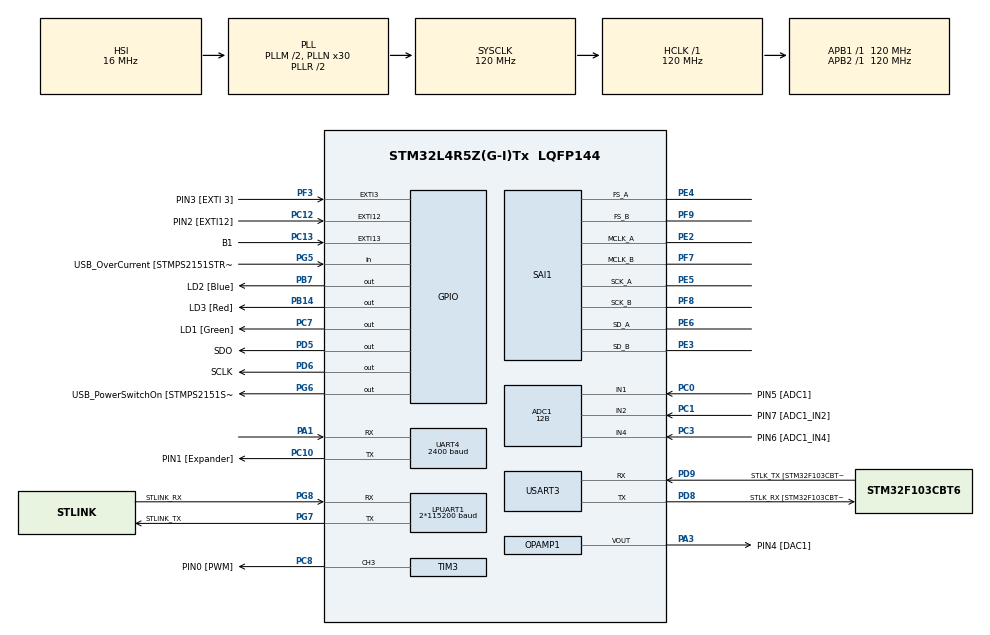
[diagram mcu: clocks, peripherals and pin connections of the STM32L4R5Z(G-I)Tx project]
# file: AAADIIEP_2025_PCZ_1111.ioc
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ADC1.Channel-1\#ChannelRegularConversion=ADC_CHANNEL_1
ADC1.Channel-2\#ChannelRegularConversion=ADC_CHANNEL_2
ADC1.Channel-3\#ChannelRegularConversion=ADC_CHANNEL_4
ADC1.Channel-4\#ChannelRegularConversion=ADC_CHANNEL_TEMPSENSOR
ADC1.Channel-5\#ChannelRegularConversion=ADC_CHANNEL_VBAT
ADC1.ClockPrescaler=ADC_CLOCK_ASYNC_DIV2
ADC1.ContinuousConvMode=DISABLE
ADC1.DMAContinuousRequests=ENABLE
ADC1.ExternalTrigConv=ADC_EXTERNALTRIG_T15_TRGO
ADC1.NbrOfConversion=5
ADC1.NbrOfConversionFlag=1
ADC1.OffsetNumber-1\#ChannelRegularConversion=ADC_OFFSET_NONE
ADC1.OffsetNumber-2\#ChannelRegularConversion=ADC_OFFSET_NONE
ADC1.OffsetNumber-3\#ChannelRegularConversion=ADC_OFFSET_NONE
ADC1.OffsetNumber-4\#ChannelRegularConversion=ADC_OFFSET_NONE
ADC1.OffsetNumber-5\#ChannelRegularConversion=ADC_OFFSET_NONE
ADC1.Rank-1\#ChannelRegularConversion=1
ADC1.Rank-2\#ChannelRegularConversion=2
ADC1.Rank-3\#ChannelRegularConversion=3
ADC1.Rank-4\#ChannelRegularConversion=4
ADC1.Rank-5\#ChannelRegularConversion=5
ADC1.Resolution=ADC_RESOLUTION_12B
ADC1.SamplingTime-1\#ChannelRegularConversion=ADC_SAMPLETIME_92CYCLES_5
ADC1.SamplingTime-2\#ChannelRegularConversion=ADC_SAMPLETIME_92CYCLES_5
ADC1.SamplingTime-3\#ChannelRegularConversion=ADC_SAMPLETIME_92CYCLES_5
ADC1.SamplingTime-4\#ChannelRegularConversion=ADC_SAMPLETIME_92CYCLES_5
ADC1.SamplingTime-5\#ChannelRegularConversion=ADC_SAMPLETIME_92CYCLES_5
ADC1.master=1
DAC1.DAC_SampleAndHold-DAC_OUT1_Int=DAC_SAMPLEANDHOLD_DISABLE
DAC1.DAC_Trigger-DAC_OUT1_Int=DAC_TRIGGER_T15_TRGO
DAC1.DAC_UserTrimming-DAC_OUT1_Int=DAC_TRIMMING_FACTORY
Dma.ADC1.3.Direction=DMA_PERIPH_TO_MEMORY
Dma.ADC1.3.EventEnable=DISABLE
Dma.ADC1.3.Instance=DMA2_Channel2
Dma.ADC1.3.MemDataAlignment=DMA_MDATAALIGN_HALFWORD
Dma.ADC1.3.MemInc=DMA_MINC_ENABLE
Dma.ADC1.3.Mode=DMA_CIRCULAR
Dma.ADC1.3.PeriphDataAlignment=DMA_PDATAALIGN_HALFWORD
Dma.ADC1.3.PeriphInc=DMA_PINC_DISABLE
Dma.ADC1.3.Polarity=HAL_DMAMUX_REQUEST_GEN_RISING
Dma.ADC1.3.Priority=DMA_PRIORITY_MEDIUM
Dma.ADC1.3.RequestNumber=1
Dma.ADC1.3.SignalID=NONE
Dma.ADC1.3.SyncEnable=DISABLE
Dma.ADC1.3.SyncPolarity=HAL_DMAMUX_SYNC_NO_EVENT
Dma.ADC1.3.SyncRequestNumber=1
Dma.ADC1.3.SyncSignalID=NONE
Dma.DAC1_CH1.2.Direction=DMA_MEMORY_TO_PERIPH
Dma.DAC1_CH1.2.EventEnable=DISABLE
Dma.DAC1_CH1.2.Instance=DMA1_Channel6
Dma.DAC1_CH1.2.MemDataAlignment=DMA_MDATAALIGN_HALFWORD
Dma.DAC1_CH1.2.MemInc=DMA_MINC_ENABLE
Dma.DAC1_CH1.2.Mode=DMA_CIRCULAR
Dma.DAC1_CH1.2.PeriphDataAlignment=DMA_PDATAALIGN_HALFWORD
Dma.DAC1_CH1.2.PeriphInc=DMA_PINC_DISABLE
Dma.DAC1_CH1.2.Polarity=HAL_DMAMUX_REQUEST_GEN_RISING
Dma.DAC1_CH1.2.Priority=DMA_PRIORITY_HIGH
Dma.DAC1_CH1.2.RequestNumber=1
Dma.DAC1_CH1.2.SignalID=NONE
Dma.DAC1_CH1.2.SyncEnable=DISABLE
Dma.DAC1_CH1.2.SyncPolarity=HAL_DMAMUX_SYNC_NO_EVENT
Dma.DAC1_CH1.2.SyncRequestNumber=1
Dma.DAC1_CH1.2.SyncSignalID=NONE
Dma.LPUART1_RX.0.Direction=DMA_PERIPH_TO_MEMORY
Dma.LPUART1_RX.0.EventEnable=DISABLE
Dma.LPUART1_RX.0.Instance=DMA1_Channel1
Dma.LPUART1_RX.0.MemDataAlignment=DMA_MDATAALIGN_BYTE
Dma.LPUART1_RX.0.MemInc=DMA_MINC_ENABLE
Dma.LPUART1_RX.0.Mode=DMA_NORMAL
Dma.LPUART1_RX.0.PeriphDataAlignment=DMA_PDATAALIGN_BYTE
Dma.LPUART1_RX.0.PeriphInc=DMA_PINC_DISABLE
Dma.LPUART1_RX.0.Polarity=HAL_DMAMUX_REQUEST_GEN_RISING
Dma.LPUART1_RX.0.Priority=DMA_PRIORITY_LOW
Dma.LPUART1_RX.0.RequestNumber=1
Dma.LPUART1_RX.0.SignalID=NONE
Dma.LPUART1_RX.0.SyncEnable=DISABLE
Dma.LPUART1_RX.0.SyncPolarity=HAL_DMAMUX_SYNC_NO_EVENT
Dma.LPUART1_RX.0.SyncRequestNumber=1
Dma.LPUART1_RX.0.SyncSignalID=NONE
Dma.LPUART1_TX.1.Direction=DMA_MEMORY_TO_PERIPH
Dma.LPUART1_TX.1.EventEnable=DISABLE
Dma.LPUART1_TX.1.Instance=DMA1_Channel2
Dma.LPUART1_TX.1.MemDataAlignment=DMA_MDATAALIGN_BYTE
Dma.LPUART1_TX.1.MemInc=DMA_MINC_ENABLE
Dma.LPUART1_TX.1.Mode=DMA_NORMAL
Dma.LPUART1_TX.1.PeriphDataAlignment=DMA_PDATAALIGN_BYTE
Dma.LPUART1_TX.1.PeriphInc=DMA_PINC_DISABLE
Dma.LPUART1_TX.1.Polarity=HAL_DMAMUX_REQUEST_GEN_RISING
Dma.LPUART1_TX.1.Priority=DMA_PRIORITY_LOW
Dma.LPUART1_TX.1.RequestNumber=1
Dma.LPUART1_TX.1.SignalID=NONE
Dma.LPUART1_TX.1.SyncEnable=DISABLE
Dma.LPUART1_TX.1.SyncPolarity=HAL_DMAMUX_SYNC_NO_EVENT
Dma.LPUART1_TX.1.SyncRequestNumber=1
Dma.LPUART1_TX.1.SyncSignalID=NONE
Dma.MEMTOMEM.8.Direction=DMA_MEMORY_TO_MEMORY
Dma.MEMTOMEM.8.EventEnable=DISABLE
Dma.MEMTOMEM.8.Instance=DMA1_Channel7
Dma.MEMTOMEM.8.MemDataAlignment=DMA_MDATAALIGN_HALFWORD
Dma.MEMTOMEM.8.MemInc=DMA_MINC_ENABLE
Dma.MEMTOMEM.8.Mode=DMA_NORMAL
Dma.MEMTOMEM.8.PeriphDataAlignment=DMA_PDATAALIGN_HALFWORD
Dma.MEMTOMEM.8.PeriphInc=DMA_PINC_ENABLE
Dma.MEMTOMEM.8.Polarity=HAL_DMAMUX_REQUEST_GEN_RISING
Dma.MEMTOMEM.8.Priority=DMA_PRIORITY_MEDIUM
Dma.MEMTOMEM.8.RequestNumber=1
Dma.MEMTOMEM.8.SignalID=NONE
Dma.MEMTOMEM.8.SyncEnable=DISABLE
Dma.MEMTOMEM.8.SyncPolarity=HAL_DMAMUX_SYNC_NO_EVENT
Dma.MEMTOMEM.8.SyncRequestNumber=1
Dma.MEMTOMEM.8.SyncSignalID=NONE
Dma.Request0=LPUART1_RX
Dma.Request1=LPUART1_TX
Dma.Request2=DAC1_CH1
Dma.Request3=ADC1
Dma.Request4=TIM3_CH3
Dma.Request5=UART4_TX
Dma.Request6=SAI1_A
Dma.Request7=SAI1_B
Dma.Request8=MEMTOMEM
Dma.SAI1_A.6.Direction=DMA_MEMORY_TO_PERIPH
Dma.SAI1_A.6.EventEnable=DISABLE
Dma.SAI1_A.6.Instance=DMA1_Channel5
Dma.SAI1_A.6.MemDataAlignment=DMA_MDATAALIGN_WORD
Dma.SAI1_A.6.MemInc=DMA_MINC_ENABLE
Dma.SAI1_A.6.Mode=DMA_CIRCULAR
Dma.SAI1_A.6.PeriphDataAlignment=DMA_PDATAALIGN_WORD
Dma.SAI1_A.6.PeriphInc=DMA_PINC_DISABLE
Dma.SAI1_A.6.Polarity=HAL_DMAMUX_REQUEST_GEN_RISING
Dma.SAI1_A.6.Priority=DMA_PRIORITY_LOW
Dma.SAI1_A.6.RequestNumber=1
Dma.SAI1_A.6.SignalID=NONE
Dma.SAI1_A.6.SyncEnable=DISABLE
Dma.SAI1_A.6.SyncPolarity=HAL_DMAMUX_SYNC_NO_EVENT
Dma.SAI1_A.6.SyncRequestNumber=1
Dma.SAI1_A.6.SyncSignalID=NONE
Dma.SAI1_B.7.Direction=DMA_PERIPH_TO_MEMORY
Dma.SAI1_B.7.EventEnable=DISABLE
Dma.SAI1_B.7.Instance=DMA2_Channel1
Dma.SAI1_B.7.MemDataAlignment=DMA_MDATAALIGN_WORD
Dma.SAI1_B.7.MemInc=DMA_MINC_ENABLE
Dma.SAI1_B.7.Mode=DMA_CIRCULAR
Dma.SAI1_B.7.PeriphDataAlignment=DMA_PDATAALIGN_WORD
Dma.SAI1_B.7.PeriphInc=DMA_PINC_DISABLE
Dma.SAI1_B.7.Polarity=HAL_DMAMUX_REQUEST_GEN_RISING
Dma.SAI1_B.7.Priority=DMA_PRIORITY_LOW
Dma.SAI1_B.7.RequestNumber=1
Dma.SAI1_B.7.SignalID=NONE
Dma.SAI1_B.7.SyncEnable=DISABLE
Dma.SAI1_B.7.SyncPolarity=HAL_DMAMUX_SYNC_NO_EVENT
Dma.SAI1_B.7.SyncRequestNumber=1
Dma.SAI1_B.7.SyncSignalID=NONE
Dma.TIM3_CH3.4.Direction=DMA_MEMORY_TO_PERIPH
Dma.TIM3_CH3.4.EventEnable=DISABLE
Dma.TIM3_CH3.4.Instance=DMA1_Channel3
Dma.TIM3_CH3.4.MemDataAlignment=DMA_MDATAALIGN_HALFWORD
Dma.TIM3_CH3.4.MemInc=DMA_MINC_ENABLE
Dma.TIM3_CH3.4.Mode=DMA_CIRCULAR
Dma.TIM3_CH3.4.PeriphDataAlignment=DMA_PDATAALIGN_HALFWORD
Dma.TIM3_CH3.4.PeriphInc=DMA_PINC_DISABLE
Dma.TIM3_CH3.4.Polarity=HAL_DMAMUX_REQUEST_GEN_RISING
Dma.TIM3_CH3.4.Priority=DMA_PRIORITY_LOW
Dma.TIM3_CH3.4.RequestNumber=1
Dma.TIM3_CH3.4.SignalID=NONE
Dma.TIM3_CH3.4.SyncEnable=DISABLE
Dma.TIM3_CH3.4.SyncPolarity=HAL_DMAMUX_SYNC_NO_EVENT
Dma.TIM3_CH3.4.SyncRequestNumber=1
Dma.TIM3_CH3.4.SyncSignalID=NONE
Dma.UART4_TX.5.Direction=DMA_MEMORY_TO_PERIPH
Dma.UART4_TX.5.EventEnable=DISABLE
Dma.UART4_TX.5.Instance=DMA1_Channel4
Dma.UART4_TX.5.MemDataAlignment=DMA_MDATAALIGN_BYTE
Dma.UART4_TX.5.MemInc=DMA_MINC_ENABLE
Dma.UART4_TX.5.Mode=DMA_NORMAL
Dma.UART4_TX.5.PeriphDataAlignment=DMA_PDATAALIGN_BYTE
Dma.UART4_TX.5.PeriphInc=DMA_PINC_DISABLE
Dma.UART4_TX.5.Polarity=HAL_DMAMUX_REQUEST_GEN_RISING
Dma.UART4_TX.5.Priority=DMA_PRIORITY_LOW
Dma.UART4_TX.5.RequestNumber=1
Dma.UART4_TX.5.SignalID=NONE
Dma.UART4_TX.5.SyncEnable=DISABLE
Dma.UART4_TX.5.SyncPolarity=HAL_DMAMUX_SYNC_NO_EVENT
Dma.UART4_TX.5.SyncRequestNumber=1
Dma.UART4_TX.5.SyncSignalID=NONE
LPUART1.BaudRate=2*115200
LPUART1.WordLength=UART_WORDLENGTH_8B
Mcu.Family=STM32L4
Mcu.Name=STM32L4R5Z(G-I)Tx
Mcu.Package=LQFP144
Mcu.UserConstants=Display_TM1637_100kHz,0
NVIC.ADC1_IRQn=true\:0\:0\:false\:false\:true\:true\:true\:true
NVIC.DMA1_Channel1_IRQn=true\:0\:0\:false\:false\:true\:false\:true\:true
NVIC.DMA1_Channel2_IRQn=true\:0\:0\:false\:false\:true\:false\:true\:true
NVIC.DMA1_Channel3_IRQn=true\:0\:0\:false\:false\:true\:false\:true\:true
NVIC.DMA1_Channel4_IRQn=true\:0\:0\:false\:false\:true\:false\:true\:true
NVIC.DMA1_Channel5_IRQn=true\:0\:0\:false\:false\:true\:false\:true\:true
NVIC.DMA1_Channel6_IRQn=true\:0\:0\:false\:false\:true\:false\:true\:true
NVIC.DMA1_Channel7_IRQn=true\:0\:0\:false\:false\:true\:true\:true\:true
NVIC.DMA2_Channel1_IRQn=true\:0\:0\:false\:false\:true\:false\:true\:true
NVIC.DMA2_Channel2_IRQn=true\:0\:0\:false\:false\:true\:false\:true\:true
NVIC.EXTI15_10_IRQn=true\:0\:0\:false\:false\:true\:true\:true\:true
NVIC.EXTI3_IRQn=true\:0\:0\:false\:false\:true\:true\:true\:true
NVIC.LPUART1_IRQn=true\:0\:0\:false\:false\:true\:true\:true\:true
NVIC.PriorityGroup=NVIC_PRIORITYGROUP_4
NVIC.SAI1_IRQn=true\:0\:0\:false\:false\:true\:true\:true\:true
NVIC.TIM1_BRK_TIM15_IRQn=true\:0\:0\:false\:false\:true\:true\:true\:true
NVIC.TIM1_TRG_COM_TIM17_IRQn=true\:0\:0\:false\:false\:true\:true\:true\:true
NVIC.TIM3_IRQn=true\:0\:0\:false\:false\:true\:true\:true\:true
NVIC.TIM6_DAC_IRQn=true\:0\:0\:false\:false\:true\:true\:true\:true
NVIC.TIM7_IRQn=true\:0\:0\:false\:false\:true\:true\:true\:true
NVIC.UART4_IRQn=true\:0\:0\:false\:false\:true\:true\:true\:true
PA1.Mode=Asynchronous
PA1.Signal=UART4_RX
PA10.GPIO_Label=USB_ID
PA10.Signal=USB_OTG_FS_ID
PA11.GPIO_Label=USB_DM
PA11.Signal=USB_OTG_FS_DM
PA12.GPIO_Label=USB_DP
PA12.Signal=USB_OTG_FS_DP
PA13\ (JTMS/SWDIO).GPIO_Label=TMS
PA13\ (JTMS/SWDIO).Mode=Serial_Wire
PA13\ (JTMS/SWDIO).Signal=SYS_JTMS-SWDIO
PA14\ (JTCK/SWCLK).GPIO_Label=TCK
PA14\ (JTCK/SWCLK).Mode=Serial_Wire
PA14\ (JTCK/SWCLK).Signal=SYS_JTCK-SWCLK
PA3.GPIO_Label=PIN4 [DAC1]
PA3.Mode=Follower-DAC_OUT1-INP
PA3.Signal=OPAMP1_VOUT
PA8.GPIO_Label=USB_SOF [TP1]
PA8.Signal=USB_OTG_FS_SOF
PA9.GPIO_Label=USB_VBUS
PA9.Signal=USB_OTG_FS_VBUS
PB14.GPIO_Label=LD3 [Red]
PB14.Signal=GPIO_Output
PB3\ (JTDO/TRACESWO).GPIO_Label=SWO
PB3\ (JTDO/TRACESWO).Signal=SYS_JTDO-SWO
PB7.GPIO_Label=LD2 [Blue]
PB7.Signal=GPIO_Output
PC0.GPIO_Label=PIN5 [ADC1]
PC0.Signal=ADCx_IN1
PC1.GPIO_Label=PIN7 [ADC1_IN2]
PC1.Signal=ADCx_IN2
PC10.GPIO_Label=PIN1 [Expander]
PC10.Mode=Asynchronous
PC10.Signal=UART4_TX
PC12.GPIO_Label=PIN2 [EXTI12]
PC12.GPIO_ModeDefaultEXTI=GPIO_MODE_IT_RISING_FALLING
PC12.Signal=GPXTI12
PC13.GPIO_Label=B1
PC13.GPIO_ModeDefaultEXTI=GPIO_MODE_IT_RISING_FALLING
PC13.Signal=GPXTI13
PC14-OSC32_IN\ (PC14).Mode=LSE-External-Oscillator
PC14-OSC32_IN\ (PC14).Signal=RCC_OSC32_IN
PC15-OSC32_OUT\ (PC15).Mode=LSE-External-Oscillator
PC15-OSC32_OUT\ (PC15).Signal=RCC_OSC32_OUT
PC3.GPIO_Label=PIN6 [ADC1_IN4]
PC3.Signal=ADCx_IN4
PC7.GPIO_Label=LD1 [Green]
PC7.Signal=GPIO_Output
PC8.GPIO_Label=PIN0 [PWM]
PC8.Signal=S_TIM3_CH3
PD5.GPIO_Label=SDO
PD5.Signal=GPIO_Output
PD6.GPIO_Label=SCLK
PD6.Signal=GPIO_Output
PD8.GPIO_Label=STLK_RX [STM32F103CBT6_PA3]
PD8.Mode=Asynchronous
PD8.Signal=USART3_TX
PD9.GPIO_Label=STLK_TX [STM32F103CBT6_PA2]
PD9.Mode=Asynchronous
PD9.Signal=USART3_RX
PE2.Mode=SAI_A_MasterWithClock
PE2.Signal=SAI1_MCLK_A
PE3.Mode=SAI_B_MasterWithClock
PE3.Signal=SAI1_SD_B
PE4.Mode=SAI_A_MasterWithClock
PE4.Signal=SAI1_FS_A
PE5.Mode=SAI_A_MasterWithClock
PE5.Signal=SAI1_SCK_A
PE6.Mode=SAI_A_MasterWithClock
PE6.Signal=SAI1_SD_A
PF3.GPIO_Label=PIN3 [EXTI 3]
PF3.GPIO_ModeDefaultEXTI=GPIO_MODE_IT_RISING_FALLING
PF3.Signal=GPXTI3
PF7.Mode=SAI_B_MasterWithClock
PF7.Signal=SAI1_MCLK_B
PF8.Mode=SAI_B_MasterWithClock
PF8.Signal=SAI1_SCK_B
PF9.Mode=SAI_B_MasterWithClock
PF9.Signal=SAI1_FS_B
PG5.GPIO_Label=USB_OverCurrent [STMPS2151STR_FAULT]
PG5.Signal=GPIO_Input
PG6.GPIO_Label=USB_PowerSwitchOn [STMPS2151STR_EN]
PG6.Signal=GPIO_Output
PG7.GPIO_Label=STLINK_TX
PG7.Mode=Asynchronous
PG7.Signal=LPUART1_TX
PG8.GPIO_Label=STLINK_RX
PG8.Mode=Asynchronous
PG8.Signal=LPUART1_RX
PH0-OSC_IN\ (PH0).Signal=RCC_OSC_IN
PH1-OSC_OUT\ (PH1).Signal=RCC_OSC_OUT
ProjectManager.HeapSize=0x200
ProjectManager.StackSize=0x400
ProjectManager.TargetToolchain=STM32CubeIDE
RCC.48MHZClocksFreq_Value=24000000
RCC.ADCCLockSelection=RCC_ADCCLKSOURCE_SYSCLK
RCC.ADCFreq_Value=120000000
RCC.AHBFreq_Value=120000000
RCC.APB1Freq_Value=120000000
RCC.APB1TimFreq_Value=120000000
RCC.APB2Freq_Value=120000000
RCC.APB2TimFreq_Value=120000000
RCC.CK48CLockSelection=RCC_USBCLKSOURCE_HSI48
RCC.CortexFreq_Value=120000000
RCC.HCLKFreq_Value=120000000
RCC.HSE_VALUE=8000000
RCC.HSI48_VALUE=48000000
RCC.HSI_VALUE=16000000
RCC.LPUART1CLockSelection=RCC_LPUART1CLKSOURCE_SYSCLK
RCC.MSI_VALUE=4000000
RCC.PLLM1=2
RCC.PLLM2=4
RCC.PLLMUL=RCC_PLL_MUL9
RCC.PLLN=30
RCC.PLLSAI1N=86
RCC.PLLSAI1P=RCC_PLLP_DIV14
RCC.PLLSAI1R=RCC_PLLR_DIV4
RCC.PLLSourceVirtual=RCC_PLLSOURCE_HSI
RCC.PRESCALERUSB=RCC_USBCLKSOURCE_PLL_DIV1_5
RCC.SYSCLKFreq_VALUE=120000000
RCC.SYSCLKSource=RCC_SYSCLKSOURCE_PLLCLK
RCC.SYSCLKSourceVirtual=RCC_SYSCLKSOURCE_PLLCLK
RCC.USBFreq_Value=48000000
RCC.VCOOutputFreq_Value=240000000
SAI1.AudioFrequency-SAI_A_MasterWithClock=SAI_AUDIO_FREQUENCY_16K
SAI1.AudioFrequency-SAI_B_MasterWithClock=SAI_AUDIO_FREQUENCY_16K
SAI1.AudioMode-SAI_A_MasterWithClock=SAI_MODEMASTER_TX
SAI1.AudioMode-SAI_B_MasterWithClock=SAI_MODEMASTER_RX
SAI1.BasicDataSize-SAI_A_MasterWithClock=SAI_PROTOCOL_DATASIZE_24BIT
SAI1.BasicDataSize-SAI_B_MasterWithClock=SAI_PROTOCOL_DATASIZE_24BIT
SAI1.ErrorAudioFreq-SAI_A_MasterWithClock=-0.01 %
SAI1.ErrorAudioFreq-SAI_B_MasterWithClock=-0.01 %
SAI1.InitProtocol-SAI_A_MasterWithClock=Enable
SAI1.InitProtocol-SAI_B_MasterWithClock=Enable
SAI1.Instance-SAI_A_MasterWithClock=SAI$Index_Block_A
SAI1.Instance-SAI_B_MasterWithClock=SAI$Index_Block_B
SAI1.MClockEnable-SAI_A_MasterWithClock=SAI_MASTERCLOCK_ENABLE
SAI1.MClockEnable-SAI_B_MasterWithClock=SAI_MASTERCLOCK_ENABLE
SAI1.RealAudioFreq-SAI_A_MasterWithClock=15.997 KHz
SAI1.RealAudioFreq-SAI_B_MasterWithClock=15.997 KHz
SAI1.VirtualMode-SAI_A_MasterWithClock=VM_MASTER
SAI1.VirtualMode-SAI_B_MasterWithClock=VM_MASTER
SAI1.VirtualProtocol-SAI_A_BASIC=VM_BASIC_PROTOCOL
SAI1.VirtualProtocol-SAI_B_BASIC=VM_BASIC_PROTOCOL
SH.ADCx_IN1.0=ADC1_IN1,IN1-Single-Ended
SH.ADCx_IN2.0=ADC1_IN2,IN2-Single-Ended
SH.ADCx_IN4.0=ADC1_IN4,IN4-Single-Ended
SH.S_TIM3_CH3.0=TIM3_CH3,PWM Generation3 CH3
TIM15.Period=100-1
TIM15.Prescaler=59
TIM15.TIM_MasterOutputTrigger=TIM_TRGO_UPDATE
TIM17.Period=10
TIM17.Prescaler=120
TIM3.Channel-PWM\ Generation3\ CH3=TIM_CHANNEL_3
TIM3.Period=12000-1
TIM3.Prescaler=0
TIM6.Period=10000
TIM6.Prescaler=1200
TIM7.Period=100
TIM7.Prescaler=120
UART4.BaudRate=2400
UART4.Mode=MODE_TX
USART3.VirtualMode-Asynchronous=VM_ASYNC
VP_ADC1_TempSens_Input.Mode=IN-TempSens
VP_ADC1_Vbat_Input.Mode=IN-Vbat
VP_DAC1_VS_DACI1.Mode=DAC_OUT1_Int
VP_SAI1_VP_$IpInstance_SAIA_SAI_BASIC.Mode=SAI_A_BASIC
VP_SAI1_VP_$IpInstance_SAIB_SAI_BASIC.Mode=SAI_B_BASIC
VP_TIM15_VS_ClockSourceINT.Mode=Internal
VP_TIM17_VS_ClockSourceINT.Mode=Enable_Timer
VP_TIM3_VS_ClockSourceINT.Mode=Internal
VP_TIM5_VS_ClockSourceINT.Mode=Internal
VP_TIM6_VS_ClockSourceINT.Mode=Enable_Timer
VP_TIM7_VS_ClockSourceINT.Mode=Enable_Timer
board=NUCLEO-L4R5ZI

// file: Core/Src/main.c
/* USER CODE BEGIN Header */
/**
  ******************************************************************************
  * @file           : main.c
  * @brief          : Main program body
  ******************************************************************************
  * @attention
  *
  * Copyright (c) 2024 STMicroelectronics.
  * All rights reserved.
  *
  * This software is licensed under terms that can be found in the LICENSE file
  * in the root directory of this software component.
  * If no LICENSE file comes with this software, it is provided AS-IS.
  *
  *Pro Fs=16000Hz
  *hodiny na SAI 16kHz > true true  2  43  14  24.5714
  *chyba 0.01% ....tj 3Hz 15997
  *
  * Scrambler DEMO
  *
  *ELM_Ulohy - nepouziva se SAI, SCARMBLER
  *ELM_Ulohy 4.11.2025
  *ELM_Ulohy konfigurace AAADIIEP + B1 + LD1-3
  *ELM_Ulohy A - ADC
  *ELM_Ulohy D - DAC
  *ELM_Ulohy I - Digital INPUT
  *ELM_Ulohy E - Expander
  *ELM_Ulohy P - PWM
  *
  *
  ******************************************************************************
  */
/* USER CODE END Header */
#include "main.h"

/* USER CODE BEGIN Includes */
#include <string.h>
#include "TimeStamp.h"
#include "ELM_Pool.h"
#include "MATLAB_2_STM32.h"
#include "math.h"
#include "TM1637_ASYNC_Display.h"
#include "ZEL_Expander.h"

#include "DSP_SAI_config.h"
#include "Scrambler_DEMO.h"
#include "arm_math.h"  // je nutne mit DSP knihovnu (napr. CMSIS)
/* USER CODE END Includes */

ADC_HandleTypeDef hadc1;
DMA_HandleTypeDef hdma_adc1;

DAC_HandleTypeDef hdac1;
DMA_HandleTypeDef hdma_dac1_ch1;

UART_HandleTypeDef hlpuart1;
UART_HandleTypeDef huart4;
UART_HandleTypeDef huart3;
DMA_HandleTypeDef hdma_lpuart1_rx;
DMA_HandleTypeDef hdma_lpuart1_tx;
DMA_HandleTypeDef hdma_uart4_tx;

OPAMP_HandleTypeDef hopamp1;

SAI_HandleTypeDef hsai_BlockA1;
SAI_HandleTypeDef hsai_BlockB1;
DMA_HandleTypeDef hdma_sai1_a;
DMA_HandleTypeDef hdma_sai1_b;

TIM_HandleTypeDef htim3;
TIM_HandleTypeDef htim5;
TIM_HandleTypeDef htim6;
TIM_HandleTypeDef htim7;
TIM_HandleTypeDef htim15;
TIM_HandleTypeDef htim17;
DMA_HandleTypeDef hdma_tim3_ch3;

DMA_HandleTypeDef hdma_memtomem_dma1_channel7;
/* USER CODE BEGIN PV */
//#define ADC_N_CHANNELS 4
#define ADC_N_CHANNELS 5
#define ADC_POS_CH01 0
#define ADC_POS_CH02 1
#define ADC_POS_CH04 2
#define ADC_POS_TEMP 3
#define ADC_POS_VBAT 4
//#define ADC_POS_VREF 3 // neni
uint16_t buf_ADC[40 * ADC_N_CHANNELS];
#define N_BUF_DAC 4000
uint16_t buf_DAC[N_BUF_DAC];

uint32_t xADC_DATA[ADC_N_CHANNELS];
uint32_t ccc;//20kHz .... 20000samples/s .... 2000 samples/100ms
#define ADC_N_DATA_100ms ADC_N_CHANNELS * 2000
uint16_t ADC_data_100ms[ADC_N_DATA_100ms];
uint16_t ADC_nData_100mS;

/* USER CODE END PV */

void SystemClock_Config(void);
void PeriphCommonClock_Config(void);
static void MX_GPIO_Init(void);
static void MX_DMA_Init(void);
static void MX_LPUART1_UART_Init(void);
static void MX_USART3_UART_Init(void);
static void MX_TIM5_Init(void);
static void MX_TIM6_Init(void);
static void MX_TIM7_Init(void);
static void MX_TIM3_Init(void);
static void MX_ADC1_Init(void);
static void MX_DAC1_Init(void);
static void MX_TIM15_Init(void);
static void MX_UART4_Init(void);
static void MX_TIM17_Init(void);
static void MX_OPAMP1_Init(void);
static void MX_SAI1_Init(void);
/* USER CODE BEGIN PFP */
int prevB1, prevPIN2, prevPIN3, DSP_mode, prevDSP_mode;
/* USER CODE END PFP */

/* USER CODE BEGIN 0 */
float DSP_tmp_Buff[BLOCK_SIZE_MAX + MAX_TAP_LEN +1];
uint16_t DSP_tmp_N;
void DataReceive_MTLB_Callback(uint16_t iD, uint32_t * xData, uint16_t nData_in_values)
{//kdyz prijdou data z matlabu, tak se toto zavola a zde je vetveni a zpracovani
	//uint32_t x_time;

	switch(iD)
	{
	case 40001://get temperature
//		DataTransmit2MTLB(40001,(uint8_t *) &teplota[nTeplota], 1);
		break;
	case 40002:
	//	DataTransmit2MTLB(40002,(uint8_t *) teplota, 61);

	case 10020: //posle ADC poslednich 100ms
		ADC_data_100ms[0] = ADC_nData_100mS; //kde to zacina
		DataTransmit2MTLB(10020,(uint8_t *) ADC_data_100ms, sizeof(ADC_data_100ms)/4);
	case 33143: //FIR
		memcpy(DSP_tmp_Buff, xData, nData_in_values * 4);
		DSP_tmp_N=nData_in_values;
		DSP_mode=1;
		break;
	case 33144: //IIR
		memcpy(DSP_tmp_Buff, xData, nData_in_values * 4);
		DSP_tmp_N=nData_in_values;
		DSP_mode=2;
		break;

	default:
		ELMP_MTLB_Callback(iD, xData, nData_in_values);
	}
}

int _tim6_n;
uint32_t nALive;

uint8_t ttimec[4];

void HAL_TIM_PeriodElapsedCallback(TIM_HandleTypeDef *htim)
{
  if(htim == &htim6)
  {
	 ELM_Callback_TIM6_100ms();

	 //HAL_GPIO_WritePin(LD3_GPIO_Port, LD3_Pin, HAL_GPIO_ReadPin(PIN6_GPIO_Port, PIN6_Pin));

	 if(_tim6_n==5) ELM_Callback_TIM6_500ms();
	 if(_tim6_n>9){
	 //if(_tim6_n>0){

		 	 	 if(HAL_GPIO_ReadPin(B1_GPIO_Port, B1_Pin))
		 	 		 TM1637_Show_Time_HHMM_Next();
		 	 	 else
		 	 	 	 TM1637_Show_Time_MMSS_Next();

		 	 	 {

		 	 		 TM1637_Time_GET(&ttimec[0], &ttimec[1], &ttimec[2]);
		 	 		 //HAL_UART_Transmit_DMA(&huart4,(uint8_t *) c, 12);

		 	 		ttimec[0]=128 + (ttimec[1]/10) * 16 + (ttimec[1] - 10*(ttimec[1]/10));
		 	 		ttimec[3]=ttimec[2];
		 	 		ttimec[1]=(ttimec[3]/10) * 16 + (ttimec[3] - 10*(ttimec[3]/10));
		 	 		 //HAL_UART_Transmit_DMA(&huart4,ttimec, 2);

		 	 	 }

		 ELM_Callback_TIM6_1s();
		 _tim6_n=0;

		 nALive++;
		 if(!m2s_Status_GET())
		 {
		     DataTransmit2MTLB(1010, (uint8_t *) &nALive, 1);

//		     char c[12]="CAhoj";
//		     c[0]=0; c[1]=0;
//		     			HAL_UART_Transmit_DMA(&huart4, (uint8_t *)c, 2);
		 }

	 }
	 _tim6_n++; return;
  }
  if(htim == &htim7)
  {
	  ELM_Callback_TIM7_100us();
  }

  TM1637_Process_Data_Display(htim);

}

void HAL_GPIO_EXTI_Callback(uint16_t GPIO_Pin)
{
	if(GPIO_Pin==B1_Pin)
	{
		if(prevB1 != HAL_GPIO_ReadPin(B1_GPIO_Port, B1_Pin))
		{
			prevB1 = HAL_GPIO_ReadPin(B1_GPIO_Port, B1_Pin);
			TimeStamp_SET_uint8(101);// osetrene tlacitko 100ms
			uint32_t dt = TimeStamp_Find(101)-TimeStamp_Find(100);
			TimeStamp_SET_uint8(100);
			if(dt>12000000*2)
			{
			//	ELM_Callback_B1();
				HAL_GPIO_WritePin(LD2_GPIO_Port, LD2_Pin, prevB1);
			}
		}

	}
	if(GPIO_Pin==PIN2_Pin)
	{
		if(prevPIN2 != HAL_GPIO_ReadPin(PIN2_GPIO_Port, PIN2_Pin))
		{
			prevPIN2 = HAL_GPIO_ReadPin(PIN2_GPIO_Port, PIN2_Pin);
			TimeStamp_SET_uint8(103);// osetrene tlacitko 100ms
			uint32_t dt = TimeStamp_Find(103)-TimeStamp_Find(102);
			TimeStamp_SET_uint8(102);
			if(dt>12000000*2)
			{
			//	ELM_Callback_B1();
				HAL_GPIO_WritePin(LD2_GPIO_Port, LD2_Pin, prevPIN2);
				prevDSP_mode = DSP_mode;
				DSP_mode = prevPIN2 + 2*prevPIN3;
			}
		}
	}
	if(GPIO_Pin==PIN3_Pin)
	{
		if(prevPIN3 != HAL_GPIO_ReadPin(PIN3_GPIO_Port, PIN3_Pin))
		{
			prevPIN3 = HAL_GPIO_ReadPin(PIN3_GPIO_Port, PIN3_Pin);
			TimeStamp_SET_uint8(105);// osetrene tlacitko 100ms
			uint32_t dt = TimeStamp_Find(105)-TimeStamp_Find(104);
			TimeStamp_SET_uint8(104);
			if(dt>12000000*2)
			{
			//	ELM_Callback_B1();
				HAL_GPIO_WritePin(LD3_GPIO_Port, LD3_Pin, prevPIN3);
				prevDSP_mode = DSP_mode;
				DSP_mode = prevPIN2 + 2*prevPIN3;
			}
		}
	}

}

void HAL_DAC_ConvCpltCallbackCh1(DAC_HandleTypeDef *hdac)
{
	  UNUSED(hdac);
//	  for(int i=0; i<10; i++)
//		  buf_DAC[i+10]=ELMP_DAC_Get_Value(i);
}

void HAL_DAC_ConvHalfCpltCallbackCh1(DAC_HandleTypeDef *hdac)
{
	  UNUSED(hdac);
//	  for(int i=0; i<10; i++)
//		  buf_DAC[i]=ELMP_DAC_Get_Value(i);
}

void ADC__ProcessSamples(uint16_t *data)
{ // 40 vzorku x 5 kanalu / 2 = 20 .... tj. prijde 20 vzorku z kazdeho kanalu ... 1ms
	ccc++;
	//memcpy(ADC_data_100ms + ADC_nData_100mS, data, 20 * sizeof(uint16_t) * ADC_N_CHANNELS);
	HAL_DMA_Start_IT(&hdma_memtomem_dma1_channel7, (uint32_t) data, (uint32_t) &(ADC_data_100ms[ADC_nData_100mS]), 20 * ADC_N_CHANNELS);
	ADC_nData_100mS += 20 * ADC_N_CHANNELS;
	if(ADC_nData_100mS >= ADC_N_DATA_100ms) ADC_nData_100mS = 0;
}

void HAL_ADC_ConvCpltCallback(ADC_HandleTypeDef *hadc)
{
  UNUSED(hadc);
//  	  uint32_t x=0, i;
//  	  for(i=0; i<10; i++)
//  	  {
//  		 x = x + buf_ADC[i * ADC_N_CHANNELS + ADC_POS_CH01 + 10*ADC_N_CHANNELS];
//  	  	 //x = x + buf_ADC[i * ADC_N_CHANNELS + ADC_POS_VBAT + 10*ADC_N_CHANNELS];
//  	  }
//  	  x = x/10;
//  	  //ELM_ADC_Callback_1ms(x);
  	  ADC__ProcessSamples(buf_ADC + 20 * ADC_N_CHANNELS);
}

void HAL_ADC_ConvHalfCpltCallback(ADC_HandleTypeDef *hadc)
{
  UNUSED(hadc);
//  ccc++;
//  	  uint32_t x=0, i;
//      for(i=0; i<10; i++)
//      {
//    	  x = x + buf_ADC[i * ADC_N_CHANNELS + ADC_POS_CH01];
//    	  //x = x + buf_ADC[i * ADC_N_CHANNELS + ADC_POS_VBAT];
//      }
//      x = x/10;
//      //ELM_ADC_Callback_1ms(x);
  	  ADC__ProcessSamples(buf_ADC);
}

void DSP_SAI_ProcessSamples(DSP_SAI_ConfigDef *hDSC)
{
	hDSC->Status_Process_DSP_Complete[0]=0;

	DSP_SAI_Set_Sample_L_Long();

	if(DSP_mode==0)
	{
		//left samples
		arm_fir_f32(hDSC->S_L_FIR, hDSC->sample_L_in, hDSC->sample_L_out, hDSC->BlockSize[0]);
		//Scramber_Proc(hDSC->sample_L_in, hDSC->sample_L_out);
		//arm_fir_f32(hDSC->S_R_FIR, hDSC->sample_L_out, hDSC->sample_R_out, hDSC->BlockSize[0]);

		//right samples
		arm_fir_f32(hDSC->S_R_FIR, hDSC->sample_R_in, hDSC->sample_R_out, hDSC->BlockSize[0]);

	}
	if(DSP_mode==1)//FIR
	{
		arm_fir_f32(hDSC->S_L_FIR, hDSC->sample_L_in, hDSC->sample_L_out, hDSC->BlockSize[0]);
		arm_fir_f32(hDSC->S_R_FIR, hDSC->sample_L_in, hDSC->sample_R_out, hDSC->BlockSize[0]);
	}
	if(DSP_mode==2)//IIR
	{
		arm_fir_f32(hDSC->S_L_FIR, hDSC->sample_L_in, hDSC->sample_L_out, hDSC->BlockSize[0]);
		//arm_biquad_cascade_df1_f32(&S_L_IIR, sample_L, sample_L1, BlockSize);
		arm_biquad_cascade_df1_f32(hDSC->S_R_IIR, hDSC->sample_L_in, hDSC->sample_R_out, hDSC->BlockSize[0]);
	}
	if(DSP_mode>2)
	{
		float a; int n=400;
		if(DSP_mode<4) n = n * DSP_mode;
		if(DSP_mode==3)
		{
			Scramber_Proc(hDSC->sample_L_in, hDSC->sample_L_out);
			for(int i=0; i<hDSC->BlockSize[0]; i++)
				hDSC->sample_R_out[i] = hDSC->sample_L_out[i];
		}
		else
		{
			for(int i=0; i<hDSC->BlockSize[0]; i++)
			{
				a = DSP_SAI_Get_Sample_L_Long(n + hDSC->BlockSize[0] - i - 1);
				hDSC->sample_L_out[i] = hDSC->sample_L_in[i] + a;
				hDSC->sample_R_out[i] = hDSC->sample_L_out[i];
			}
		}
	}
	hDSC->Status_Process_DSP_Complete[0]=1;

}

uint16_t buf_PWM[200];
/* USER CODE END 0 */

int main(void)
{

  /* USER CODE BEGIN 1 */
	ELM_POOL_INIT();
	DSP_mode=0;
	prevDSP_mode=0;
  /* USER CODE END 1 */

  /* MCU Configuration--------------------------------------------------------*/

  /* Reset of all peripherals, Initializes the Flash interface and the Systick. */
  HAL_Init();

  /* Configure the system clock */
  SystemClock_Config();

  /* Configure the peripherals common clocks */
  PeriphCommonClock_Config();

  /* Initialize all configured peripherals */
  MX_GPIO_Init();
  MX_DMA_Init();
  MX_LPUART1_UART_Init();
  MX_USART3_UART_Init();
  MX_TIM5_Init();
  MX_TIM6_Init();
  MX_TIM7_Init();
  MX_TIM3_Init();
  MX_ADC1_Init();
  MX_DAC1_Init();
  MX_TIM15_Init();
  MX_UART4_Init();
  MX_TIM17_Init();
  MX_OPAMP1_Init();
  MX_SAI1_Init();
  /* USER CODE BEGIN 2 */

  m2s_Init(&hlpuart1);
  TimeStamp_INIT(&htim5);
  HAL_TIM_Base_Start_IT(&htim6);
  HAL_TIM_Base_Start_IT(&htim7);
  ELMP_LogProbe_8bits_Init();
  ELMP_LogProbe_Show(0);
  ELM_TIM_Init(&htim6, &htim7);

  TimeStamp_SET_uint8(100);

  HAL_TIM_Base_Start_IT(&htim15);//20kHz pro ADC

  HAL_ADCEx_Calibration_Start(&hadc1, ADC_SINGLE_ENDED);
  HAL_Delay(50);
  // 5xch 20+20samles tj 1ms callback
  HAL_StatusTypeDef adc_status = HAL_ADC_Start_DMA(&hadc1, (uint32_t *) buf_ADC, 40 * ADC_N_CHANNELS);
  UNUSED(adc_status);

  HAL_OPAMP_SelfCalibrate(&hopamp1);
  HAL_Delay(50);
  HAL_OPAMP_Start(&hopamp1);

  DAC_ChannelConfTypeDef sConfig = {0};
  sConfig.DAC_SampleAndHold = DAC_SAMPLEANDHOLD_DISABLE;
  sConfig.DAC_Trigger = DAC_TRIGGER_T15_TRGO;
  sConfig.DAC_HighFrequency = DAC_HIGH_FREQUENCY_INTERFACE_MODE_DISABLE;
  sConfig.DAC_OutputBuffer = DAC_OUTPUTBUFFER_DISABLE;
  sConfig.DAC_ConnectOnChipPeripheral = DAC_CHIPCONNECT_ENABLE;
  sConfig.DAC_UserTrimming = DAC_TRIMMING_FACTORY;
  HAL_DACEx_SelfCalibrate(&hdac1, &sConfig, DAC_CHANNEL_1);
  HAL_Delay(50);
  if (HAL_DAC_ConfigChannel(&hdac1, &sConfig, DAC_CHANNEL_1) != HAL_OK)
    {
      Error_Handler();
    }

  float s;
  for(int i=0; i<N_BUF_DAC; i++)//20kHz
  {
  	  s = 2000.0f * sin(2.0f*M_PI*i*100.0f/20000);// -1...1
  	  buf_DAC[i]= s + 2048; //offset
  	  //  	buf_DAC[i]=i;
  }

  HAL_DAC_Start_DMA(&hdac1, DAC_CHANNEL_1, (uint32_t *)buf_DAC, N_BUF_DAC, DAC_ALIGN_12B_R);

  // PWM data - 200 vzorků, period-12000, f_PWM=10kHz
  // tady to jeste nechodí 06-Nov-2025 14:35:54
  for(int i=0; i<200; i++)
  {
	  s = sin(2.0*M_PI*i*50/10000);// -1...1
	  s=s+1;// 0...2
	  s=s/2;// 0...1
	  buf_PWM[i]= s * 12000;

  }

  HAL_TIM_PWM_Start_DMA(&htim3, TIM_CHANNEL_3,(uint32_t *) buf_PWM, 200);

    //ZelExpander_Init(&huart4);

  //DSP_SAI_Init(2*180, &hsai_BlockA1, &hsai_BlockB1);
  DSP_SAI_ConfigDef* hD =    DSP_SAI_Init(1000, &hsai_BlockA1, &hsai_BlockB1); UNUSED(hD);

 //odladeni fce na long data
//  DSP_SAI_Stop();
//  int i, j, n=5;
//  for(j=0; j<40; j++)
//  {
//	  for(i=0; i<n; i++)
//		  hD->sample_L_in[i] = i + j*n;
//
//	  DSP_SAI_Set_Sample_L_Long();
//  }
//  float aa=DSP_SAI_Get_Sample_L_Long(50);
//  DSP_SAI_Stop();

//  	  Scramber_Init(hD->BlockSize);

  /* USER CODE END 2 */

  /* Infinite loop */
  while (1)
  {

    /* USER CODE BEGIN 3 */
	  m2s_Process();

	  if(prevDSP_mode != DSP_mode)
	  {
		  prevDSP_mode = DSP_mode;
		  //DSP_SAI_ConfigDef* hD;
		  DSP_SAI_Stop();
		  if(DSP_mode==0)// proste echo
		  {
			  float B1__=1;
			  DSP_SAI_Set_FIR(&B1__, 1, &B1__, 1);
		  }
		  if(DSP_mode==1) // nastavit FIR
		  {
			  memcpy((float *)hD->S_R_FIR->pCoeffs, DSP_tmp_Buff, DSP_tmp_N * 4);
			  arm_fir_init_f32(hD->S_R_FIR, DSP_tmp_N/5, hD->S_R_FIR->pCoeffs, hD->S_R_FIR->pState, hD->BlockSize[0]);
		  }
		  if(DSP_mode==2) //nastavit IIR
		  {

			  memcpy((float *)hD->S_R_IIR->pCoeffs, DSP_tmp_Buff, DSP_tmp_N * 4);
			  arm_biquad_cascade_df1_init_f32(hD->S_R_IIR, DSP_tmp_N/5, hD->S_R_IIR->pCoeffs, hD->S_R_IIR->pState);

		  }
		  if(DSP_mode==3)// ozvena ... filtr 1 a + 1*x[n-1600]
		  {
			  float B1__=1;
			  DSP_SAI_Set_FIR(&B1__, 1, &B1__, 1);
		  }
		  HAL_Delay(100);
		  DSP_SAI_Start();
	  }

  }
  /* USER CODE END 3 */
}

void SystemClock_Config(void)
{
  RCC_OscInitTypeDef RCC_OscInitStruct = {0};
  RCC_ClkInitTypeDef RCC_ClkInitStruct = {0};

  /** Configure the main internal regulator output voltage
  */
  if (HAL_PWREx_ControlVoltageScaling(PWR_REGULATOR_VOLTAGE_SCALE1_BOOST) != HAL_OK)
  {
    Error_Handler();
  }

  /** Initializes the RCC Oscillators according to the specified parameters
  * in the RCC_OscInitTypeDef structure.
  */
  RCC_OscInitStruct.OscillatorType = RCC_OSCILLATORTYPE_HSI;
  RCC_OscInitStruct.HSIState = RCC_HSI_ON;
  RCC_OscInitStruct.HSICalibrationValue = RCC_HSICALIBRATION_DEFAULT;
  RCC_OscInitStruct.PLL.PLLState = RCC_PLL_ON;
  RCC_OscInitStruct.PLL.PLLSource = RCC_PLLSOURCE_HSI;
  RCC_OscInitStruct.PLL.PLLM = 2;
  RCC_OscInitStruct.PLL.PLLN = 30;
  RCC_OscInitStruct.PLL.PLLP = RCC_PLLP_DIV2;
  RCC_OscInitStruct.PLL.PLLQ = RCC_PLLQ_DIV2;
  RCC_OscInitStruct.PLL.PLLR = RCC_PLLR_DIV2;
  if (HAL_RCC_OscConfig(&RCC_OscInitStruct) != HAL_OK)
  {
    Error_Handler();
  }

  /** Initializes the CPU, AHB and APB buses clocks
  */
  RCC_ClkInitStruct.ClockType = RCC_CLOCKTYPE_HCLK|RCC_CLOCKTYPE_SYSCLK
                              |RCC_CLOCKTYPE_PCLK1|RCC_CLOCKTYPE_PCLK2;
  RCC_ClkInitStruct.SYSCLKSource = RCC_SYSCLKSOURCE_PLLCLK;
  RCC_ClkInitStruct.AHBCLKDivider = RCC_SYSCLK_DIV1;
  RCC_ClkInitStruct.APB1CLKDivider = RCC_HCLK_DIV1;
  RCC_ClkInitStruct.APB2CLKDivider = RCC_HCLK_DIV1;

  if (HAL_RCC_ClockConfig(&RCC_ClkInitStruct, FLASH_LATENCY_5) != HAL_OK)
  {
    Error_Handler();
  }
}

void PeriphCommonClock_Config(void)
{
  RCC_PeriphCLKInitTypeDef PeriphClkInit = {0};

  /** Initializes the peripherals clock
  */
  PeriphClkInit.PeriphClockSelection = RCC_PERIPHCLK_SAI1;
  PeriphClkInit.Sai1ClockSelection = RCC_SAI1CLKSOURCE_PLLSAI1;
  PeriphClkInit.PLLSAI1.PLLSAI1Source = RCC_PLLSOURCE_HSI;
  PeriphClkInit.PLLSAI1.PLLSAI1M = 4;
  PeriphClkInit.PLLSAI1.PLLSAI1N = 86;
  PeriphClkInit.PLLSAI1.PLLSAI1P = RCC_PLLP_DIV14;
  PeriphClkInit.PLLSAI1.PLLSAI1Q = RCC_PLLQ_DIV2;
  PeriphClkInit.PLLSAI1.PLLSAI1R = RCC_PLLR_DIV4;
  PeriphClkInit.PLLSAI1.PLLSAI1ClockOut = RCC_PLLSAI1_SAI1CLK;
  if (HAL_RCCEx_PeriphCLKConfig(&PeriphClkInit) != HAL_OK)
  {
    Error_Handler();
  }
}

static void MX_ADC1_Init(void)
{

  ADC_ChannelConfTypeDef sConfig = {0};

  /** Common config
  */
  hadc1.Instance = ADC1;
  hadc1.Init.ClockPrescaler = ADC_CLOCK_ASYNC_DIV2;
  hadc1.Init.Resolution = ADC_RESOLUTION_12B;
  hadc1.Init.DataAlign = ADC_DATAALIGN_RIGHT;
  hadc1.Init.ScanConvMode = ADC_SCAN_ENABLE;
  hadc1.Init.EOCSelection = ADC_EOC_SINGLE_CONV;
  hadc1.Init.LowPowerAutoWait = DISABLE;
  hadc1.Init.ContinuousConvMode = DISABLE;
  hadc1.Init.NbrOfConversion = 5;
  hadc1.Init.DiscontinuousConvMode = DISABLE;
  hadc1.Init.ExternalTrigConv = ADC_EXTERNALTRIG_T15_TRGO;
  hadc1.Init.ExternalTrigConvEdge = ADC_EXTERNALTRIGCONVEDGE_RISING;
  hadc1.Init.DMAContinuousRequests = ENABLE;
  hadc1.Init.Overrun = ADC_OVR_DATA_PRESERVED;
  hadc1.Init.OversamplingMode = DISABLE;
  if (HAL_ADC_Init(&hadc1) != HAL_OK)
  {
    Error_Handler();
  }

  /** Configure Regular Channel
  */
  sConfig.Channel = ADC_CHANNEL_1;
  sConfig.Rank = ADC_REGULAR_RANK_1;
  sConfig.SamplingTime = ADC_SAMPLETIME_92CYCLES_5;
  sConfig.SingleDiff = ADC_SINGLE_ENDED;
  sConfig.OffsetNumber = ADC_OFFSET_NONE;
  sConfig.Offset = 0;
  if (HAL_ADC_ConfigChannel(&hadc1, &sConfig) != HAL_OK)
  {
    Error_Handler();
  }

  /** Configure Regular Channel
  */
  sConfig.Channel = ADC_CHANNEL_2;
  sConfig.Rank = ADC_REGULAR_RANK_2;
  if (HAL_ADC_ConfigChannel(&hadc1, &sConfig) != HAL_OK)
  {
    Error_Handler();
  }

  /** Configure Regular Channel
  */
  sConfig.Channel = ADC_CHANNEL_4;
  sConfig.Rank = ADC_REGULAR_RANK_3;
  if (HAL_ADC_ConfigChannel(&hadc1, &sConfig) != HAL_OK)
  {
    Error_Handler();
  }

  /** Configure Regular Channel
  */
  sConfig.Channel = ADC_CHANNEL_TEMPSENSOR;
  sConfig.Rank = ADC_REGULAR_RANK_4;
  if (HAL_ADC_ConfigChannel(&hadc1, &sConfig) != HAL_OK)
  {
    Error_Handler();
  }

  /** Configure Regular Channel
  */
  sConfig.Channel = ADC_CHANNEL_VBAT;
  sConfig.Rank = ADC_REGULAR_RANK_5;
  if (HAL_ADC_ConfigChannel(&hadc1, &sConfig) != HAL_OK)
  {
    Error_Handler();
  }

}

static void MX_DAC1_Init(void)
{

  DAC_ChannelConfTypeDef sConfig = {0};

  /** DAC Initialization
  */
  hdac1.Instance = DAC1;
  if (HAL_DAC_Init(&hdac1) != HAL_OK)
  {
    Error_Handler();
  }

  /** DAC channel OUT1 config
  */
  sConfig.DAC_SampleAndHold = DAC_SAMPLEANDHOLD_DISABLE;
  sConfig.DAC_Trigger = DAC_TRIGGER_T15_TRGO;
  sConfig.DAC_HighFrequency = DAC_HIGH_FREQUENCY_INTERFACE_MODE_ABOVE_80MHZ;
  sConfig.DAC_OutputBuffer = DAC_OUTPUTBUFFER_DISABLE;
  sConfig.DAC_ConnectOnChipPeripheral = DAC_CHIPCONNECT_ENABLE;
  sConfig.DAC_UserTrimming = DAC_TRIMMING_FACTORY;
  if (HAL_DAC_ConfigChannel(&hdac1, &sConfig, DAC_CHANNEL_1) != HAL_OK)
  {
    Error_Handler();
  }

}

static void MX_LPUART1_UART_Init(void)
{

  hlpuart1.Instance = LPUART1;
  hlpuart1.Init.BaudRate = 2*115200;
  hlpuart1.Init.WordLength = UART_WORDLENGTH_8B;
  hlpuart1.Init.StopBits = UART_STOPBITS_1;
  hlpuart1.Init.Parity = UART_PARITY_NONE;
  hlpuart1.Init.Mode = UART_MODE_TX_RX;
  hlpuart1.Init.HwFlowCtl = UART_HWCONTROL_NONE;
  hlpuart1.Init.OneBitSampling = UART_ONE_BIT_SAMPLE_DISABLE;
  hlpuart1.Init.ClockPrescaler = UART_PRESCALER_DIV1;
  hlpuart1.AdvancedInit.AdvFeatureInit = UART_ADVFEATURE_NO_INIT;
  hlpuart1.FifoMode = UART_FIFOMODE_DISABLE;
  if (HAL_UART_Init(&hlpuart1) != HAL_OK)
  {
    Error_Handler();
  }
  if (HAL_UARTEx_SetTxFifoThreshold(&hlpuart1, UART_TXFIFO_THRESHOLD_1_8) != HAL_OK)
  {
    Error_Handler();
  }
  if (HAL_UARTEx_SetRxFifoThreshold(&hlpuart1, UART_RXFIFO_THRESHOLD_1_8) != HAL_OK)
  {
    Error_Handler();
  }
  if (HAL_UARTEx_DisableFifoMode(&hlpuart1) != HAL_OK)
  {
    Error_Handler();
  }

}

static void MX_UART4_Init(void)
{

  huart4.Instance = UART4;
  huart4.Init.BaudRate = 2400;
  huart4.Init.WordLength = UART_WORDLENGTH_8B;
  huart4.Init.StopBits = UART_STOPBITS_1;
  huart4.Init.Parity = UART_PARITY_NONE;
  huart4.Init.Mode = UART_MODE_TX;
  huart4.Init.HwFlowCtl = UART_HWCONTROL_NONE;
  huart4.Init.OverSampling = UART_OVERSAMPLING_16;
  huart4.Init.OneBitSampling = UART_ONE_BIT_SAMPLE_DISABLE;
  huart4.Init.ClockPrescaler = UART_PRESCALER_DIV1;
  huart4.AdvancedInit.AdvFeatureInit = UART_ADVFEATURE_NO_INIT;
  if (HAL_UART_Init(&huart4) != HAL_OK)
  {
    Error_Handler();
  }
  if (HAL_UARTEx_SetTxFifoThreshold(&huart4, UART_TXFIFO_THRESHOLD_1_8) != HAL_OK)
  {
    Error_Handler();
  }
  if (HAL_UARTEx_SetRxFifoThreshold(&huart4, UART_RXFIFO_THRESHOLD_1_8) != HAL_OK)
  {
    Error_Handler();
  }
  if (HAL_UARTEx_DisableFifoMode(&huart4) != HAL_OK)
  {
    Error_Handler();
  }

}

static void MX_USART3_UART_Init(void)
{

  huart3.Instance = USART3;
  huart3.Init.BaudRate = 115200;
  huart3.Init.WordLength = UART_WORDLENGTH_8B;
  huart3.Init.StopBits = UART_STOPBITS_1;
  huart3.Init.Parity = UART_PARITY_NONE;
  huart3.Init.Mode = UART_MODE_TX_RX;
  huart3.Init.HwFlowCtl = UART_HWCONTROL_NONE;
  huart3.Init.OverSampling = UART_OVERSAMPLING_16;
  huart3.Init.OneBitSampling = UART_ONE_BIT_SAMPLE_DISABLE;
  huart3.Init.ClockPrescaler = UART_PRESCALER_DIV1;
  huart3.AdvancedInit.AdvFeatureInit = UART_ADVFEATURE_NO_INIT;
  if (HAL_UART_Init(&huart3) != HAL_OK)
  {
    Error_Handler();
  }
  if (HAL_UARTEx_SetTxFifoThreshold(&huart3, UART_TXFIFO_THRESHOLD_1_8) != HAL_OK)
  {
    Error_Handler();
  }
  if (HAL_UARTEx_SetRxFifoThreshold(&huart3, UART_RXFIFO_THRESHOLD_1_8) != HAL_OK)
  {
    Error_Handler();
  }
  if (HAL_UARTEx_DisableFifoMode(&huart3) != HAL_OK)
  {
    Error_Handler();
  }

}

static void MX_OPAMP1_Init(void)
{

  hopamp1.Instance = OPAMP1;
  hopamp1.Init.PowerSupplyRange = OPAMP_POWERSUPPLY_LOW;
  hopamp1.Init.Mode = OPAMP_FOLLOWER_MODE;
  hopamp1.Init.NonInvertingInput = OPAMP_NONINVERTINGINPUT_DAC_CH;
  hopamp1.Init.PowerMode = OPAMP_POWERMODE_NORMALPOWER;
  hopamp1.Init.UserTrimming = OPAMP_TRIMMING_FACTORY;
  if (HAL_OPAMP_Init(&hopamp1) != HAL_OK)
  {
    Error_Handler();
  }

}

static void MX_SAI1_Init(void)
{

  hsai_BlockA1.Instance = SAI1_Block_A;
  hsai_BlockA1.Init.AudioMode = SAI_MODEMASTER_TX;
  hsai_BlockA1.Init.Synchro = SAI_ASYNCHRONOUS;
  hsai_BlockA1.Init.OutputDrive = SAI_OUTPUTDRIVE_DISABLE;
  hsai_BlockA1.Init.NoDivider = SAI_MASTERDIVIDER_ENABLE;
  hsai_BlockA1.Init.FIFOThreshold = SAI_FIFOTHRESHOLD_EMPTY;
  hsai_BlockA1.Init.AudioFrequency = SAI_AUDIO_FREQUENCY_16K;
  hsai_BlockA1.Init.SynchroExt = SAI_SYNCEXT_DISABLE;
  hsai_BlockA1.Init.MonoStereoMode = SAI_STEREOMODE;
  hsai_BlockA1.Init.CompandingMode = SAI_NOCOMPANDING;
  hsai_BlockA1.Init.TriState = SAI_OUTPUT_NOTRELEASED;
  if (HAL_SAI_InitProtocol(&hsai_BlockA1, SAI_I2S_STANDARD, SAI_PROTOCOL_DATASIZE_24BIT, 2) != HAL_OK)
  {
    Error_Handler();
  }
  hsai_BlockB1.Instance = SAI1_Block_B;
  hsai_BlockB1.Init.AudioMode = SAI_MODEMASTER_RX;
  hsai_BlockB1.Init.Synchro = SAI_ASYNCHRONOUS;
  hsai_BlockB1.Init.OutputDrive = SAI_OUTPUTDRIVE_DISABLE;
  hsai_BlockB1.Init.NoDivider = SAI_MASTERDIVIDER_ENABLE;
  hsai_BlockB1.Init.FIFOThreshold = SAI_FIFOTHRESHOLD_EMPTY;
  hsai_BlockB1.Init.AudioFrequency = SAI_AUDIO_FREQUENCY_16K;
  hsai_BlockB1.Init.SynchroExt = SAI_SYNCEXT_DISABLE;
  hsai_BlockB1.Init.MonoStereoMode = SAI_STEREOMODE;
  hsai_BlockB1.Init.CompandingMode = SAI_NOCOMPANDING;
  if (HAL_SAI_InitProtocol(&hsai_BlockB1, SAI_I2S_STANDARD, SAI_PROTOCOL_DATASIZE_24BIT, 2) != HAL_OK)
  {
    Error_Handler();
  }

}

static void MX_TIM3_Init(void)
{

  TIM_ClockConfigTypeDef sClockSourceConfig = {0};
  TIM_MasterConfigTypeDef sMasterConfig = {0};
  TIM_OC_InitTypeDef sConfigOC = {0};

  htim3.Instance = TIM3;
  htim3.Init.Prescaler = 0;
  htim3.Init.CounterMode = TIM_COUNTERMODE_UP;
  htim3.Init.Period = 12000-1;
  htim3.Init.ClockDivision = TIM_CLOCKDIVISION_DIV1;
  htim3.Init.AutoReloadPreload = TIM_AUTORELOAD_PRELOAD_DISABLE;
  if (HAL_TIM_Base_Init(&htim3) != HAL_OK)
  {
    Error_Handler();
  }
  sClockSourceConfig.ClockSource = TIM_CLOCKSOURCE_INTERNAL;
  if (HAL_TIM_ConfigClockSource(&htim3, &sClockSourceConfig) != HAL_OK)
  {
    Error_Handler();
  }
  if (HAL_TIM_PWM_Init(&htim3) != HAL_OK)
  {
    Error_Handler();
  }
  sMasterConfig.MasterOutputTrigger = TIM_TRGO_RESET;
  sMasterConfig.MasterSlaveMode = TIM_MASTERSLAVEMODE_DISABLE;
  if (HAL_TIMEx_MasterConfigSynchronization(&htim3, &sMasterConfig) != HAL_OK)
  {
    Error_Handler();
  }
  sConfigOC.OCMode = TIM_OCMODE_PWM1;
  sConfigOC.Pulse = 0;
  sConfigOC.OCPolarity = TIM_OCPOLARITY_HIGH;
  sConfigOC.OCFastMode = TIM_OCFAST_DISABLE;
  if (HAL_TIM_PWM_ConfigChannel(&htim3, &sConfigOC, TIM_CHANNEL_3) != HAL_OK)
  {
    Error_Handler();
  }
  HAL_TIM_MspPostInit(&htim3);

}

static void MX_TIM5_Init(void)
{

  TIM_ClockConfigTypeDef sClockSourceConfig = {0};
  TIM_MasterConfigTypeDef sMasterConfig = {0};

  htim5.Instance = TIM5;
  htim5.Init.Prescaler = 0;
  htim5.Init.CounterMode = TIM_COUNTERMODE_UP;
  htim5.Init.Period = 4294967295;
  htim5.Init.ClockDivision = TIM_CLOCKDIVISION_DIV1;
  htim5.Init.AutoReloadPreload = TIM_AUTORELOAD_PRELOAD_DISABLE;
  if (HAL_TIM_Base_Init(&htim5) != HAL_OK)
  {
    Error_Handler();
  }
  sClockSourceConfig.ClockSource = TIM_CLOCKSOURCE_INTERNAL;
  if (HAL_TIM_ConfigClockSource(&htim5, &sClockSourceConfig) != HAL_OK)
  {
    Error_Handler();
  }
  sMasterConfig.MasterOutputTrigger = TIM_TRGO_RESET;
  sMasterConfig.MasterSlaveMode = TIM_MASTERSLAVEMODE_DISABLE;
  if (HAL_TIMEx_MasterConfigSynchronization(&htim5, &sMasterConfig) != HAL_OK)
  {
    Error_Handler();
  }

}

static void MX_TIM6_Init(void)
{

  TIM_MasterConfigTypeDef sMasterConfig = {0};

  htim6.Instance = TIM6;
  htim6.Init.Prescaler = 1200;
  htim6.Init.CounterMode = TIM_COUNTERMODE_UP;
  htim6.Init.Period = 10000;
  htim6.Init.AutoReloadPreload = TIM_AUTORELOAD_PRELOAD_DISABLE;
  if (HAL_TIM_Base_Init(&htim6) != HAL_OK)
  {
    Error_Handler();
  }
  sMasterConfig.MasterOutputTrigger = TIM_TRGO_RESET;
  sMasterConfig.MasterSlaveMode = TIM_MASTERSLAVEMODE_DISABLE;
  if (HAL_TIMEx_MasterConfigSynchronization(&htim6, &sMasterConfig) != HAL_OK)
  {
    Error_Handler();
  }

}

static void MX_TIM7_Init(void)
{

  TIM_MasterConfigTypeDef sMasterConfig = {0};

  htim7.Instance = TIM7;
  htim7.Init.Prescaler = 120;
  htim7.Init.CounterMode = TIM_COUNTERMODE_UP;
  htim7.Init.Period = 100;
  htim7.Init.AutoReloadPreload = TIM_AUTORELOAD_PRELOAD_DISABLE;
  if (HAL_TIM_Base_Init(&htim7) != HAL_OK)
  {
    Error_Handler();
  }
  sMasterConfig.MasterOutputTrigger = TIM_TRGO_RESET;
  sMasterConfig.MasterSlaveMode = TIM_MASTERSLAVEMODE_DISABLE;
  if (HAL_TIMEx_MasterConfigSynchronization(&htim7, &sMasterConfig) != HAL_OK)
  {
    Error_Handler();
  }

}

static void MX_TIM15_Init(void)
{

  TIM_ClockConfigTypeDef sClockSourceConfig = {0};
  TIM_MasterConfigTypeDef sMasterConfig = {0};

  htim15.Instance = TIM15;
  htim15.Init.Prescaler = 59;
  htim15.Init.CounterMode = TIM_COUNTERMODE_UP;
  htim15.Init.Period = 100-1;
  htim15.Init.ClockDivision = TIM_CLOCKDIVISION_DIV1;
  htim15.Init.RepetitionCounter = 0;
  htim15.Init.AutoReloadPreload = TIM_AUTORELOAD_PRELOAD_DISABLE;
  if (HAL_TIM_Base_Init(&htim15) != HAL_OK)
  {
    Error_Handler();
  }
  sClockSourceConfig.ClockSource = TIM_CLOCKSOURCE_INTERNAL;
  if (HAL_TIM_ConfigClockSource(&htim15, &sClockSourceConfig) != HAL_OK)
  {
    Error_Handler();
  }
  sMasterConfig.MasterOutputTrigger = TIM_TRGO_UPDATE;
  sMasterConfig.MasterSlaveMode = TIM_MASTERSLAVEMODE_DISABLE;
  if (HAL_TIMEx_MasterConfigSynchronization(&htim15, &sMasterConfig) != HAL_OK)
  {
    Error_Handler();
  }

}

static void MX_TIM17_Init(void)
{

  htim17.Instance = TIM17;
  htim17.Init.Prescaler = 120;
  htim17.Init.CounterMode = TIM_COUNTERMODE_UP;
  htim17.Init.Period = 10;
  htim17.Init.ClockDivision = TIM_CLOCKDIVISION_DIV1;
  htim17.Init.RepetitionCounter = 0;
  htim17.Init.AutoReloadPreload = TIM_AUTORELOAD_PRELOAD_DISABLE;
  if (HAL_TIM_Base_Init(&htim17) != HAL_OK)
  {
    Error_Handler();
  }

}

static void MX_DMA_Init(void)
{

  /* DMA controller clock enable */
  __HAL_RCC_DMAMUX1_CLK_ENABLE();
  __HAL_RCC_DMA1_CLK_ENABLE();
  __HAL_RCC_DMA2_CLK_ENABLE();

  /* Configure DMA request hdma_memtomem_dma1_channel7 on DMA1_Channel7 */
  hdma_memtomem_dma1_channel7.Instance = DMA1_Channel7;
  hdma_memtomem_dma1_channel7.Init.Request = DMA_REQUEST_MEM2MEM;
  hdma_memtomem_dma1_channel7.Init.Direction = DMA_MEMORY_TO_MEMORY;
  hdma_memtomem_dma1_channel7.Init.PeriphInc = DMA_PINC_ENABLE;
  hdma_memtomem_dma1_channel7.Init.MemInc = DMA_MINC_ENABLE;
  hdma_memtomem_dma1_channel7.Init.PeriphDataAlignment = DMA_PDATAALIGN_HALFWORD;
  hdma_memtomem_dma1_channel7.Init.MemDataAlignment = DMA_MDATAALIGN_HALFWORD;
  hdma_memtomem_dma1_channel7.Init.Mode = DMA_NORMAL;
  hdma_memtomem_dma1_channel7.Init.Priority = DMA_PRIORITY_MEDIUM;
  if (HAL_DMA_Init(&hdma_memtomem_dma1_channel7) != HAL_OK)
  {
    Error_Handler( );
  }

  /* DMA interrupt init */
  /* DMA1_Channel1_IRQn interrupt configuration */
  HAL_NVIC_SetPriority(DMA1_Channel1_IRQn, 0, 0);
  HAL_NVIC_EnableIRQ(DMA1_Channel1_IRQn);
  /* DMA1_Channel2_IRQn interrupt configuration */
  HAL_NVIC_SetPriority(DMA1_Channel2_IRQn, 0, 0);
  HAL_NVIC_EnableIRQ(DMA1_Channel2_IRQn);
  /* DMA1_Channel3_IRQn interrupt configuration */
  HAL_NVIC_SetPriority(DMA1_Channel3_IRQn, 0, 0);
  HAL_NVIC_EnableIRQ(DMA1_Channel3_IRQn);
  /* DMA1_Channel4_IRQn interrupt configuration */
  HAL_NVIC_SetPriority(DMA1_Channel4_IRQn, 0, 0);
  HAL_NVIC_EnableIRQ(DMA1_Channel4_IRQn);
  /* DMA1_Channel5_IRQn interrupt configuration */
  HAL_NVIC_SetPriority(DMA1_Channel5_IRQn, 0, 0);
  HAL_NVIC_EnableIRQ(DMA1_Channel5_IRQn);
  /* DMA1_Channel6_IRQn interrupt configuration */
  HAL_NVIC_SetPriority(DMA1_Channel6_IRQn, 0, 0);
  HAL_NVIC_EnableIRQ(DMA1_Channel6_IRQn);
  /* DMA1_Channel7_IRQn interrupt configuration */
  HAL_NVIC_SetPriority(DMA1_Channel7_IRQn, 0, 0);
  HAL_NVIC_EnableIRQ(DMA1_Channel7_IRQn);
  /* DMA2_Channel1_IRQn interrupt configuration */
  HAL_NVIC_SetPriority(DMA2_Channel1_IRQn, 0, 0);
  HAL_NVIC_EnableIRQ(DMA2_Channel1_IRQn);
  /* DMA2_Channel2_IRQn interrupt configuration */
  HAL_NVIC_SetPriority(DMA2_Channel2_IRQn, 0, 0);
  HAL_NVIC_EnableIRQ(DMA2_Channel2_IRQn);

}

static void MX_GPIO_Init(void)
{
  GPIO_InitTypeDef GPIO_InitStruct = {0};

  /* GPIO Ports Clock Enable */
  __HAL_RCC_GPIOE_CLK_ENABLE();
  __HAL_RCC_GPIOC_CLK_ENABLE();
  __HAL_RCC_GPIOF_CLK_ENABLE();
  __HAL_RCC_GPIOH_CLK_ENABLE();
  __HAL_RCC_GPIOA_CLK_ENABLE();
  __HAL_RCC_GPIOB_CLK_ENABLE();
  __HAL_RCC_GPIOD_CLK_ENABLE();
  __HAL_RCC_GPIOG_CLK_ENABLE();
  HAL_PWREx_EnableVddIO2();

  /*Configure GPIO pin Output Level */
  HAL_GPIO_WritePin(GPIOB, LD3_Pin|LD2_Pin, GPIO_PIN_RESET);

  /*Configure GPIO pin Output Level */
  HAL_GPIO_WritePin(USB_PowerSwitchOn_GPIO_Port, USB_PowerSwitchOn_Pin, GPIO_PIN_RESET);

  /*Configure GPIO pin Output Level */
  HAL_GPIO_WritePin(LD1_GPIO_Port, LD1_Pin, GPIO_PIN_RESET);

  /*Configure GPIO pin Output Level */
  HAL_GPIO_WritePin(GPIOD, SDO_Pin|SCLK_Pin, GPIO_PIN_RESET);

  /*Configure GPIO pins : B1_Pin PIN2_Pin */
  GPIO_InitStruct.Pin = B1_Pin|PIN2_Pin;
  GPIO_InitStruct.Mode = GPIO_MODE_IT_RISING_FALLING;
  GPIO_InitStruct.Pull = GPIO_NOPULL;
  HAL_GPIO_Init(GPIOC, &GPIO_InitStruct);

  /*Configure GPIO pin : PIN3_Pin */
  GPIO_InitStruct.Pin = PIN3_Pin;
  GPIO_InitStruct.Mode = GPIO_MODE_IT_RISING_FALLING;
  GPIO_InitStruct.Pull = GPIO_NOPULL;
  HAL_GPIO_Init(PIN3_GPIO_Port, &GPIO_InitStruct);

  /*Configure GPIO pins : LD3_Pin LD2_Pin */
  GPIO_InitStruct.Pin = LD3_Pin|LD2_Pin;
  GPIO_InitStruct.Mode = GPIO_MODE_OUTPUT_PP;
  GPIO_InitStruct.Pull = GPIO_NOPULL;
  GPIO_InitStruct.Speed = GPIO_SPEED_FREQ_LOW;
  HAL_GPIO_Init(GPIOB, &GPIO_InitStruct);

  /*Configure GPIO pin : USB_OverCurrent_Pin */
  GPIO_InitStruct.Pin = USB_OverCurrent_Pin;
  GPIO_InitStruct.Mode = GPIO_MODE_INPUT;
  GPIO_InitStruct.Pull = GPIO_NOPULL;
  HAL_GPIO_Init(USB_OverCurrent_GPIO_Port, &GPIO_InitStruct);

  /*Configure GPIO pin : USB_PowerSwitchOn_Pin */
  GPIO_InitStruct.Pin = USB_PowerSwitchOn_Pin;
  GPIO_InitStruct.Mode = GPIO_MODE_OUTPUT_PP;
  GPIO_InitStruct.Pull = GPIO_NOPULL;
  GPIO_InitStruct.Speed = GPIO_SPEED_FREQ_LOW;
  HAL_GPIO_Init(USB_PowerSwitchOn_GPIO_Port, &GPIO_InitStruct);

  /*Configure GPIO pin : LD1_Pin */
  GPIO_InitStruct.Pin = LD1_Pin;
  GPIO_InitStruct.Mode = GPIO_MODE_OUTPUT_PP;
  GPIO_InitStruct.Pull = GPIO_NOPULL;
  GPIO_InitStruct.Speed = GPIO_SPEED_FREQ_LOW;
  HAL_GPIO_Init(LD1_GPIO_Port, &GPIO_InitStruct);

  /*Configure GPIO pins : USB_SOF_Pin USB_ID_Pin USB_DM_Pin USB_DP_Pin */
  GPIO_InitStruct.Pin = USB_SOF_Pin|USB_ID_Pin|USB_DM_Pin|USB_DP_Pin;
  GPIO_InitStruct.Mode = GPIO_MODE_AF_PP;
  GPIO_InitStruct.Pull = GPIO_NOPULL;
  GPIO_InitStruct.Speed = GPIO_SPEED_FREQ_VERY_HIGH;
  GPIO_InitStruct.Alternate = GPIO_AF10_OTG_FS;
  HAL_GPIO_Init(GPIOA, &GPIO_InitStruct);

  /*Configure GPIO pin : USB_VBUS_Pin */
  GPIO_InitStruct.Pin = USB_VBUS_Pin;
  GPIO_InitStruct.Mode = GPIO_MODE_INPUT;
  GPIO_InitStruct.Pull = GPIO_NOPULL;
  HAL_GPIO_Init(USB_VBUS_GPIO_Port, &GPIO_InitStruct);

  /*Configure GPIO pins : SDO_Pin SCLK_Pin */
  GPIO_InitStruct.Pin = SDO_Pin|SCLK_Pin;
  GPIO_InitStruct.Mode = GPIO_MODE_OUTPUT_PP;
  GPIO_InitStruct.Pull = GPIO_NOPULL;
  GPIO_InitStruct.Speed = GPIO_SPEED_FREQ_LOW;
  HAL_GPIO_Init(GPIOD, &GPIO_InitStruct);

  /* EXTI interrupt init*/
  HAL_NVIC_SetPriority(EXTI3_IRQn, 0, 0);
  HAL_NVIC_EnableIRQ(EXTI3_IRQn);

  HAL_NVIC_SetPriority(EXTI15_10_IRQn, 0, 0);
  HAL_NVIC_EnableIRQ(EXTI15_10_IRQn);

}

void Error_Handler(void)
{
  __disable_irq();
  while (1)
  {
  }
}
